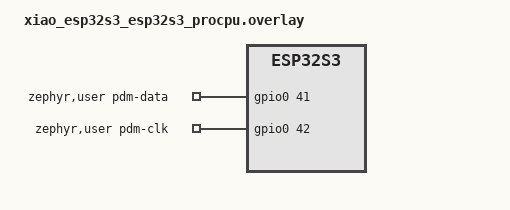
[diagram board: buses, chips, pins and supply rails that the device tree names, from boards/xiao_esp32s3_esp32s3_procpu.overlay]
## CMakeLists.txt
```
# SPDX-License-Identifier: Apache-2.0
# pdmbench（V0.4.x M17b/Q-36）：PDM 麦克风驱动 bring-up 载体（板级，非 twister）。
cmake_minimum_required(VERSION 3.20.0)
find_package(Zephyr REQUIRED HINTS $ENV{ZEPHYR_BASE})
project(pdmbench)
target_sources(app PRIVATE src/main.c)
```

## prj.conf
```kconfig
# SPDX-License-Identifier: Apache-2.0
CONFIG_TS_CORE=y
CONFIG_TS_SAFETY=y
CONFIG_TS_HAL=y
CONFIG_TS_DRV_PDM=y
CONFIG_PINCTRL=y
CONFIG_CACHE_MANAGEMENT=y
CONFIG_PRINTK=y
CONFIG_MAIN_STACK_SIZE=8192
```

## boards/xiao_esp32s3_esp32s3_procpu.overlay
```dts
/* pdmbench：PDM 引脚（Sense 板载 MP34DT05；双源核验 2026-10-13）：
 * GPIO41 = DATA 入、GPIO42 = CLK 出（zephyr,user specs；矩阵路由在驱动）。 */
/ {
	zephyr,user {
		pdm-data-gpios = <&gpio0 41 0>;
		pdm-clk-gpios = <&gpio0 42 0>;
	};
};
```

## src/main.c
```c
/* SPDX-License-Identifier: Apache-2.0 */
/* pdmbench（V0.4.x M17b/Q-36）：PDM 驱动 bring-up 判据载体。
 * 判据（PDMB PASS）= 连续 8 帧采集：len 恒 640、非全零、非饱和
 * （|max| < 30000）、min != max（信号活动）。PDMB2 逐帧 min/max/mean
 * 供人工判读（静音=小波动、吹气/敲击=大幅波动）。 */
#include <string.h>
#include <zephyr/kernel.h>
#include <zephyr/sys/printk.h>
#include <ts/hal.h>

#define FRAMES 8

static uint8_t frame[640];

int main(void)
{
	printk("PDMB0 pdmbench start\n");
	if (ts_drv_pdm_init() != 0) {
		printk("PDMB FAIL init\n");
		return 1;
	}
	printk("PDMB1 init ok\n");
	int16_t gmin = 32767, gmax = -32768;

	for (int i = 0; i < FRAMES; i++) {
		int n = ts_drv_pdm_capture(frame, sizeof(frame));

		if (n != 640) {
			printk("PDMB FAIL frame %d rc=%d（无帧/超时——时钟或引脚位）\n",
			       i, n);
			return 1;
		}
		int16_t mn = 32767, mx = -32768;
		int64_t sum = 0;
		const int16_t *s = (const int16_t *)frame;

		for (int j = 0; j < 320; j++) {
			if (s[j] < mn) mn = s[j];
			if (s[j] > mx) mx = s[j];
			sum += s[j];
		}
		if (mn < gmin) gmin = mn;
		if (mx > gmax) gmax = mx;
		printk("PDMB2 f=%d len=%d min=%d max=%d mean=%d\n",
		       i, n, mn, mx, (int)(sum / 320));
		k_sleep(K_MSEC(100));
	}
	bool alive = (gmin != gmax) && (gmax < 30000) && (gmin > -30000)
		     && !(gmin == 0 && gmax == 0);

	printk("PDMB3 span=[%d,%d] alive=%d\n", gmin, gmax, (int)alive);
	printk(alive ? "PDMB PASS\n" : "PDMB FAIL flat/saturated\n");
	for (;;) {
		k_sleep(K_SECONDS(5));
		printk("PDMB idle\n");
	}
	return 0;
}
```
